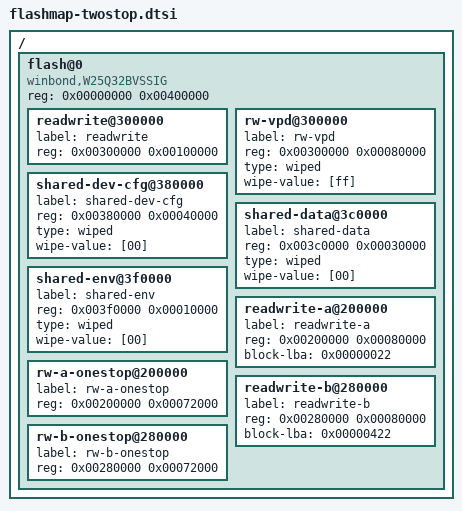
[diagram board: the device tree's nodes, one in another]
/*
 * Copyright (c) 2011 The Chromium OS Authors. All rights reserved.
 * Use of this source code is governed by a BSD-style license that can be
 * found in the LICENSE file.
 */

/*
 * This is the flash map (fmap) for a twostop firmware. It defines all the areas
 * that Chrome OS expects to find in its firmware device. The device is split
 * into a number of top-level sections, and within each are several areas.
 *
 * Available flags for each entry are: read-only, compresed.
 * All sections will be marked static in the fmap.
 */

/include/ "onestop-layout.dtsi"
/include/ "flashmap-twostop-ro-submap.dtsi"

/*
 * TODO: Although we can squeeze R/O and R/W blobs into 2 MB, we do not do
 * so because:
 *
 * - (A minor reason) Not every 4 MB flash chip can write-protect just the
 *   first 1 MB.
 *
 * - (The main reason) We do not know how many tools or scripts implicitly
 *   assume that R/O section consumes the first half 2 MB.
 *
 * In the long run, we should find and fix all those tools and scripts that
 * have incorrect implicit assumption of R/O section, but for now, we just
 * cannot squeeze the image size down to 2 MB at the risk of wrongly write-
 * protecting the R/W blobs.
 */

/ {
	flash@0 {
		#address-cells = <1>;
		#size-cells = <1>;
		compatible = "winbond,W25Q32BVSSIG", "cfi-flash",
			     "chromeos,flashmap";
		reg = <0x00000000 0x00400000>;

		/* ---- Section: Readwrite ---- */
		readwrite@300000 {
			label = "readwrite";
			reg = <0x00300000 0x00100000>;
		};
		rw-vpd@300000 {
			label = "rw-vpd";
			reg = <0x00300000 0x00080000>;
			type = "wiped";
			wipe-value = [ff];
		};
		shared-dev-cfg@380000 {
			label = "shared-dev-cfg";
			reg = <0x00380000 0x00040000>;
			type = "wiped";
			wipe-value = [00];
		};
		shared-data@3c0000 {
			label = "shared-data";
			reg = <0x003c0000 0x00030000>;
			type = "wiped";
			wipe-value = [00];
		};
		shared-env@3f0000 {
			label = "shared-env";
			reg = <0x003f0000 0x00010000>;

			/*
			 * We could put the dev environment here, but U-Boot
			 * has a default built in. Devs can 'saveenv' to set
			 * this up.
			 */
			type = "wiped";
			wipe-value = [00];
		};

		/* ---- Section: Readwrite Slot A and B ---- */
		/* So far only a onestop blob is put into readwrite A/B slot */
		readwrite-a@200000 {
			label = "readwrite-a";
			reg = <0x00200000 0x00080000>;
			block-lba = <0x00000022>;
		};
		rw-a-onestop@200000 {
			label = "rw-a-onestop";
			reg = <0x00200000 0x00072000>;
		};
		readwrite-b@280000 {
			label = "readwrite-b";
			reg = <0x00280000 0x00080000>;
			block-lba = <0x00000422>;
		};
		rw-b-onestop@280000 {
			label = "rw-b-onestop";
			reg = <0x00280000 0x00072000>;
		};
	};
};
